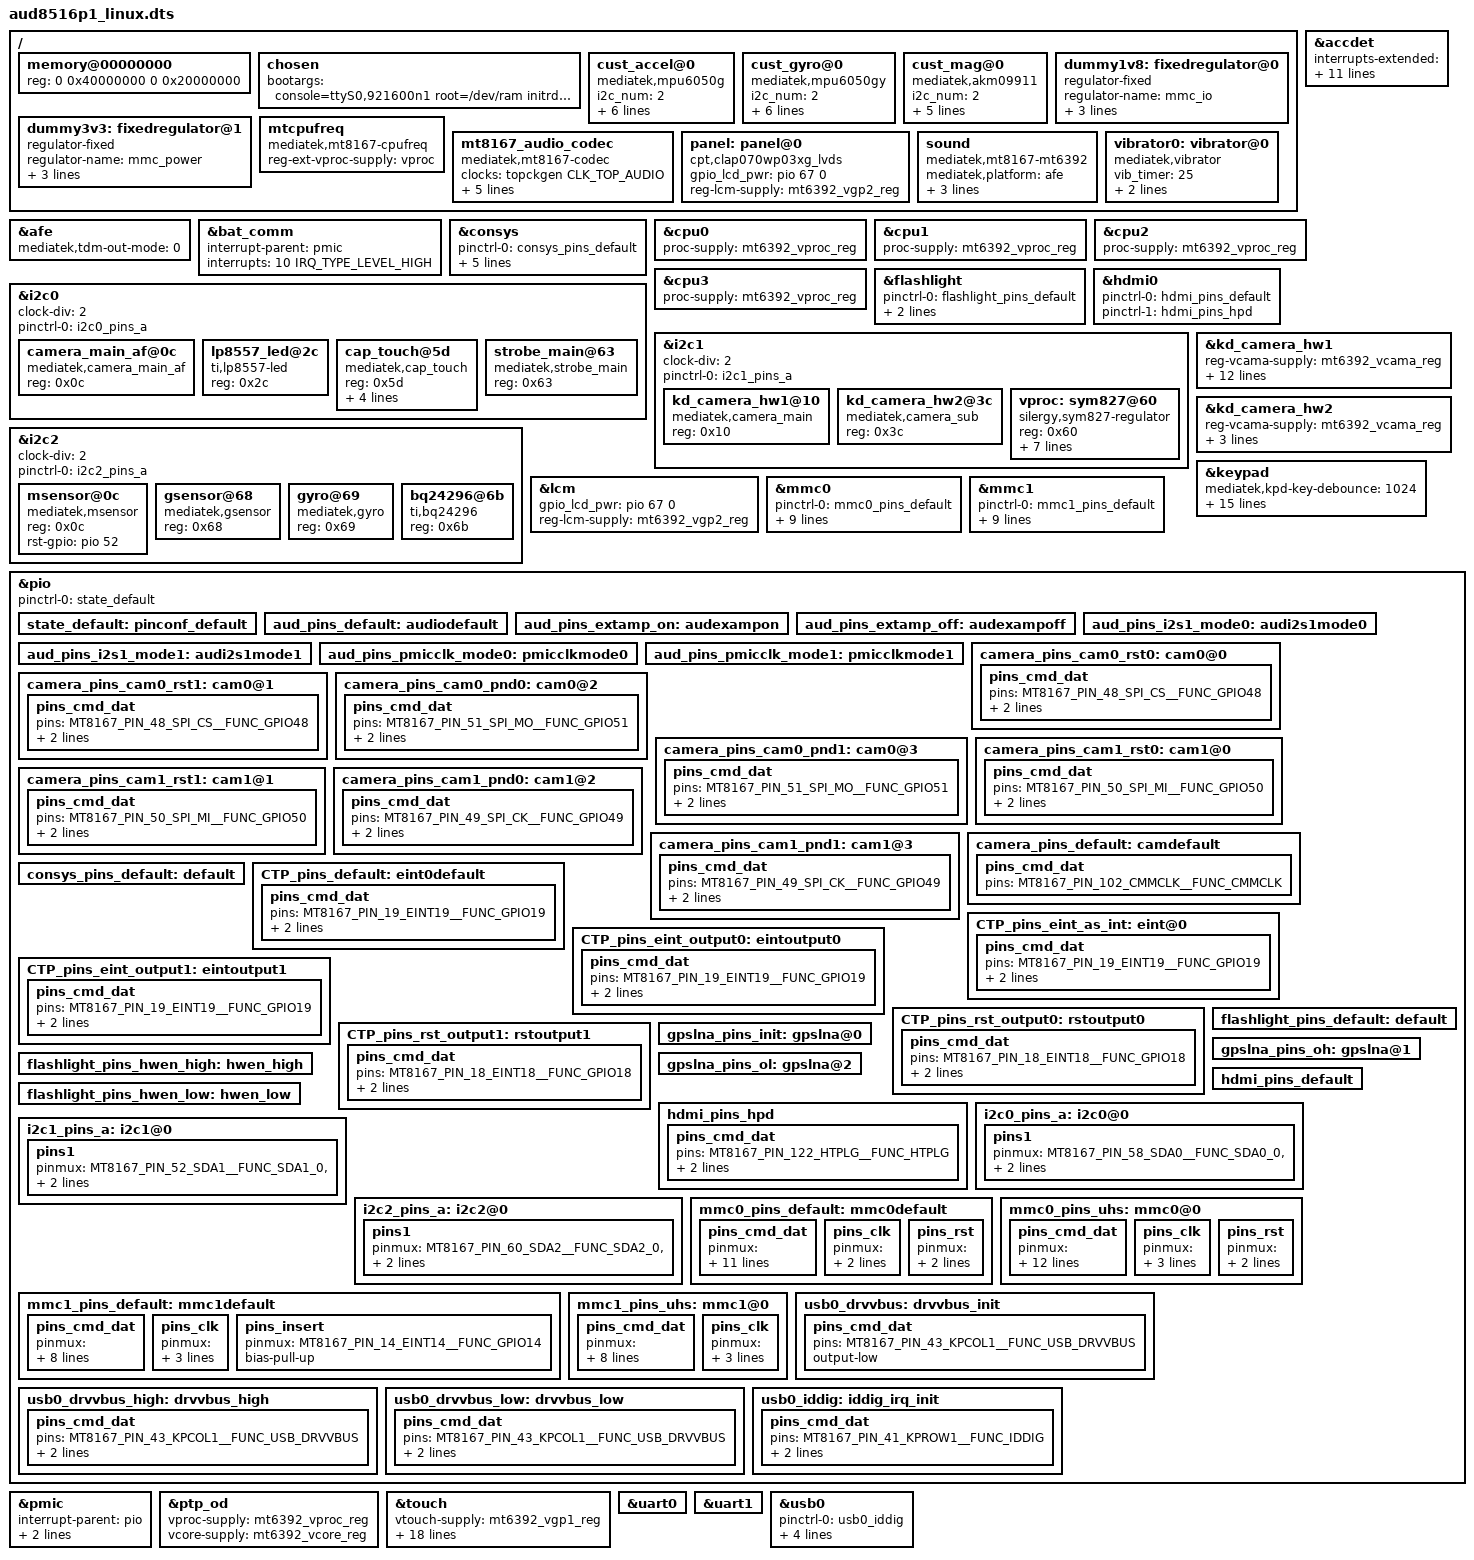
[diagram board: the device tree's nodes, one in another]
/*
 * Copyright (c) 2014-2015 MediaTek Inc.
 *
 * This program is free software; you can redistribute it and/or modify
 * it under the terms of the GNU General Public License version 2 as
 * published by the Free Software Foundation.
 *
 * This program is distributed in the hope that it will be useful,
 * MERCHANTABILITY or FITNESS FOR A PARTICULAR PURPOSE.  See the
 * GNU General Public License for more details.
 */

/dts-v1/;

#include "mt8167.dtsi"
#include "mt6392.dtsi"
#include "aud8516p1_linux_bat_setting.dtsi"

/ {
	memory@00000000 {
		device_type = "memory";
		reg = <0 0x40000000 0 0x20000000>;
	};

	/* chosen */
	chosen {
		bootargs = "console=ttyS0,921600n1 root=/dev/ram initrd=0x44000200,0x200000";
	};

/* sensor standardization */
	cust_accel@0 {
		compatible = "mediatek,mpu6050g";
		i2c_num	= <2>;
		i2c_addr = <0x68 0 0 0>;
		direction = <7>;
		power_id = <0xffff>;
		power_vol = <0>;
		firlen = <0>;
		is_batch_supported = <0>;
	};

	cust_gyro@0 {
		compatible = "mediatek,mpu6050gy";
		i2c_num = <2>;
		i2c_addr = <0x68 0 0 0>;
		direction = <7>;
		power_id = <0xffff>;
		power_vol = <0>;
		firlen = <0>;
		is_batch_supported = <0>;
	};

	cust_mag@0 {
		compatible = "mediatek,akm09911";
		i2c_num = <2>;
		i2c_addr = <0x0C 0 0 0>;
		direction = <6>;
		power_id = <0xffff>;
		power_vol = <0>;
		is_batch_supported			= <0>;
	};
/* sensor gpio standization */

	dummy1v8: fixedregulator@0 {
		compatible = "regulator-fixed";
		regulator-name = "mmc_io";
		regulator-min-microvolt = <1800000>;
		regulator-max-microvolt = <1800000>;
		regulator-always-on;
	};

	dummy3v3: fixedregulator@1 {
		compatible = "regulator-fixed";
		regulator-name = "mmc_power";
		regulator-min-microvolt = <3300000>;
		regulator-max-microvolt = <3300000>;
		regulator-always-on;
	};

	mtcpufreq {
		compatible = "mediatek,mt8167-cpufreq";
		reg-ext-vproc-supply = <&vproc>;
	};

	mt8167_audio_codec: mt8167_audio_codec {
		compatible = "mediatek,mt8167-codec";
		clocks = <&topckgen CLK_TOP_AUDIO>;
		clock-names = "bus";
		mediatek,afe-regmap = <&afe>;
		mediatek,apmixedsys-regmap = <&apmixedsys>;
		mediatek,pwrap-regmap = <&pwrap>;
		mediatek,speaker-mode = <0>; /* 0(CLASSD) 1(CLASSAB) */
		mediatek,dmic-wire-mode = <1>; /* 0(ONE_WIRE) 1(TWO_WIRE) */
	};

	panel: panel@0 {
		compatible = "cpt,clap070wp03xg_lvds";
		gpio_lcd_pwr = <&pio 67 0>;
		reg-lcm-supply = <&mt6392_vgp2_reg>;
	};

	sound: sound {
		compatible = "mediatek,mt8167-mt6392";
		mediatek,platform = <&afe>;
		pinctrl-names = "default", "extamp_on", "extamp_off";
		pinctrl-0 = <&aud_pins_default>;
		pinctrl-1 = <&aud_pins_extamp_on>;
		pinctrl-2 = <&aud_pins_extamp_off>;
		status = "okay";
	};

	vibrator0:vibrator@0 {
		compatible = "mediatek,vibrator";
		vib_timer = <25>;
		vib_limit = <9>;
		vib_vol= <5>;
	};
};

&accdet {
	interrupts-extended = <&sysirq GIC_SPI 152 IRQ_TYPE_LEVEL_LOW>,
			<&pio 16 IRQ_TYPE_LEVEL_HIGH>;
	eint-debounce = <256000>;
	accdet-gpio = <&pio 16 0>;
	accdet-mic-vol = <7>;
	headset-mode-setting = <0x500 0x500 1 0x1f0 0x800 0x800 0x20>;
	accdet-plugout-debounce = <20>;
	/*1:ACC mode, 2:low cost without in bias, 6:low cost with in bias*/
	accdet-mic-mode = <1>;
	/*0--MD_MAX--UP_MAX--DW_MAX*/
	headset-three-key-threshold = <0 80 220 500>;
	/*0--MD_MAX--VOICE_MAX--UP_MAX--DW_MAX*/
	headset-four-key-threshold = <0 58 121 192 450>;
	status = "okay";
};

&afe {
	/* 0(HDMI) 1(I2S) 2(TDM) */
	mediatek,tdm-out-mode = <0>;
};

&bat_comm {
	interrupt-parent = <&pmic>;
	interrupts = <10 IRQ_TYPE_LEVEL_HIGH>;
};

&consys {
	pinctrl-names = "default", "gps_lna_state_init", "gps_lna_state_oh", "gps_lna_state_ol";
	pinctrl-0 = <&consys_pins_default>;
	pinctrl-1 = <&gpslna_pins_init>;
	pinctrl-2 = <&gpslna_pins_oh>;
	pinctrl-3 = <&gpslna_pins_ol>;
	vcn18-supply = <&mt6392_vcn18_reg>;
	vcn35-supply = <&mt6392_vcn35_reg>;
	status = "okay";
};

&cpu0 {
	proc-supply = <&mt6392_vproc_reg>;
};

&cpu1 {
	proc-supply = <&mt6392_vproc_reg>;
};

&cpu2 {
	proc-supply = <&mt6392_vproc_reg>;
};

&cpu3 {
	proc-supply = <&mt6392_vproc_reg>;
};

&flashlight {
	pinctrl-names = "default", "hwen_high", "hwen_low";
	pinctrl-0 = <&flashlight_pins_default>;
	pinctrl-1 = <&flashlight_pins_hwen_high>;
	pinctrl-2 = <&flashlight_pins_hwen_low>;
	status = "okay";
};

&hdmi0 {
	pinctrl-names = "default", "hdmi_hpd";
	pinctrl-0 = <&hdmi_pins_default>;
	pinctrl-1 = <&hdmi_pins_hpd>;
	status = "okay";
};

&i2c0 {
	clock-div = <2>;
	pinctrl-names = "default";
	pinctrl-0 = <&i2c0_pins_a>;
	status = "okay";

	camera_main_af@0c {
		compatible = "mediatek,camera_main_af";
		reg = <0x0c>;
	};

	lp8557_led@2c {
		compatible = "ti,lp8557-led";
		reg = <0x2c>;
	};

	cap_touch@5d {
		compatible = "mediatek,cap_touch";
		reg = <0x5d>;
		interrupt-parent = <&pio>;
		interrupts = <19 IRQ_TYPE_EDGE_FALLING>;
		int-gpio = <&pio 19 0>;
		rst-gpio = <&pio 18 0>;
	};

	strobe_main@63 {
		compatible = "mediatek,strobe_main";
		reg = <0x63>;
	};
};

&i2c1 {
	clock-div = <2>;
	pinctrl-names = "default";
	pinctrl-0 = <&i2c1_pins_a>;
	status = "okay";

	kd_camera_hw1@10 {
		compatible = "mediatek,camera_main";
		reg = <0x10>;
	};

	kd_camera_hw2@3c {
		compatible = "mediatek,camera_sub";
		reg = <0x3c>;
	};

	vproc: sym827@60 {
		compatible = "silergy,sym827-regulator";
		reg = <0x60>;
		regulator-name = "vproc";
		regulator-min-microvolt = <600000>;
		regulator-max-microvolt = <1387500>;
		regulator-enable-ramp-delay = <400>;
		regulator-ramp-delay = <8333>;
		regulator-always-on;
		vsel-gpio = <&pio 34 0>;
	};
};

&i2c2 {
	clock-div = <2>;
	pinctrl-names = "default";
	pinctrl-0 = <&i2c2_pins_a>;
	status = "okay";

	msensor@0c {
		compatible = "mediatek,msensor";
		reg = <0x0c>;
		rst-gpio = <&pio 52 0>;
	};

	gsensor@68 {
		compatible = "mediatek,gsensor";
		reg = <0x68>;
	};

	gyro@69 {
		compatible = "mediatek,gyro";
		reg = <0x69>;
	};

	bq24296@6b {
		compatible = "ti,bq24296";
		reg = <0x6b>;
	};
};

/* Main Cam */
&kd_camera_hw1 {
	reg-vcama-supply = <&mt6392_vcama_reg>;		/* AVDD */
	reg-vcamd-supply = <&mt6392_vcamd_reg>;		/* DVDD */
	reg-vcamio-supply = <&mt6392_vcamio_reg>;	/* DOVDD */
	reg-vcamaf-supply = <&mt6392_vcamaf_reg>;	/* AFVDD */

	pinctrl-names = "default", "cam0_rst0", "cam0_rst1", "cam0_pnd0", "cam0_pnd1",
			"cam1_rst0", "cam1_rst1", "cam1_pnd0", "cam1_pnd1", "cam_ldo0_0", "cam_ldo0_1";
	pinctrl-0 = <&camera_pins_default>;
	pinctrl-1 = <&camera_pins_cam0_rst0>;
	pinctrl-2 = <&camera_pins_cam0_rst1>;
	pinctrl-3 = <&camera_pins_cam0_pnd0>;
	pinctrl-4 = <&camera_pins_cam0_pnd1>;
	pinctrl-5 = <&camera_pins_cam1_rst0>;
	pinctrl-6 = <&camera_pins_cam1_rst1>;
	pinctrl-7 = <&camera_pins_cam1_pnd0>;
	pinctrl-8 = <&camera_pins_cam1_pnd1>;
	status = "okay";
};

/* Sub Cam */
/* Same power pins as Main, actually, it can be commented */
&kd_camera_hw2{
	reg-vcama-supply = <&mt6392_vcama_reg>;		/* AVDD */
	reg-vcamd-supply = <&mt6392_vcamd_reg>;		/* DVDD */
	reg-vcamio-supply = <&mt6392_vcamio_reg>;	/* DOVDD */
	reg-vcamaf-supply = <&mt6392_vcamaf_reg>;	/* AFVDD */
};

&keypad {
	mediatek,kpd-key-debounce = <1024>;
	mediatek,kpd-sw-pwrkey = <116>;
	mediatek,kpd-hw-pwrkey = <8>;
	mediatek,kpd-sw-rstkey  = <114>;
	mediatek,kpd-hw-rstkey = <17>;
	mediatek,kpd-use-extend-type = <0>;
	/*HW Keycode [0~71] -> Linux Keycode*/
	mediatek,kpd-hw-map-num = <72>;
	mediatek,kpd-hw-init-map = <115 0 0 0 0 0 0 0 0 0 0 0 0 0 0 0 0 0 0 0 0 0 0 0
			0 0 0 0 0 0 0 0 0 0 0 0 0 0 0 0 0 0 0 0 0 0 0 0
			0 0 0 0 0 0 0 0 0 0 0 0 0 0 0 0 0 0 0 0 0 0 0 0 >;
	mediatek,kpd-pwrkey-eint-gpio = <0>;
	mediatek,kpd-pwkey-gpio-din  = <0>;
	mediatek,kpd-hw-dl-key0 = <0>;
	mediatek,kpd-hw-dl-key1 = <17>;
	mediatek,kpd-hw-dl-key2 = <8>;
	mediatek,kpd-hw-recovery-key = <17>;
	mediatek,kpd-hw-factory-key  = <0>;
};

&lcm {
	gpio_lcd_pwr = <&pio 67 0>;
	reg-lcm-supply = <&mt6392_vgp2_reg>;
};

&mmc0 {
	pinctrl-names = "default", "state_uhs";
	pinctrl-0 = <&mmc0_pins_default>;
	pinctrl-1 = <&mmc0_pins_uhs>;
	status = "okay";
	bus-width = <8>;
	max-frequency = <200000000>;
	cap-mmc-highspeed;
	mmc-hs200-1_8v;
	cap-mmc-hw-reset;
	vmmc-supply = <&mt6392_vemc3v3_reg>;
	vqmmc-supply = <&mt6392_vio18_reg>;
	non-removable;
};

&mmc1 {
	pinctrl-names = "default", "state_uhs";
	pinctrl-0 = <&mmc1_pins_default>;
	pinctrl-1 = <&mmc1_pins_uhs>;
	status = "okay";
	bus-width = <4>;
	max-frequency = <200000000>;
	cap-sd-highspeed;
	sd-uhs-sdr50;
	sd-uhs-sdr104;
	cd-gpios = <&pio 14 0>;
	vmmc-supply = <&mt6392_vmch_reg>;
	vqmmc-supply = <&mt6392_vmc_reg>;
};

&pio {
	pinctrl-names = "default";
	pinctrl-0 = <&state_default>;

	state_default:pinconf_default {
	};

	aud_pins_default: audiodefault {
	};

	aud_pins_extamp_on: audexampon {
	};

	aud_pins_extamp_off: audexampoff {
	};

	aud_pins_i2s1_mode0: audi2s1mode0 {
	};

	aud_pins_i2s1_mode1: audi2s1mode1 {
	};

	aud_pins_pmicclk_mode0: pmicclkmode0 {
	};

	aud_pins_pmicclk_mode1: pmicclkmode1 {
	};

	/* CAMERA GPIO standardization */
	/* Project Dependency : tb8167m1 */
	camera_pins_cam0_rst0: cam0@0 {
		pins_cmd_dat {
			pins = <MT8167_PIN_48_SPI_CS__FUNC_GPIO48>;/*GPIO_CAMERA_CMRST_PIN*/
			slew-rate = <1>; /*direction 0:in, 1:out*/
			output-low;/*direction out used only. output_low or high*/
		};
	};
	camera_pins_cam0_rst1: cam0@1 {
		pins_cmd_dat {
			pins = <MT8167_PIN_48_SPI_CS__FUNC_GPIO48>;/*GPIO_CAMERA_CMRST_PIN*/
			slew-rate = <1>;
			output-high;
		};
	};
	camera_pins_cam0_pnd0: cam0@2 {
		pins_cmd_dat {
			pins = <MT8167_PIN_51_SPI_MO__FUNC_GPIO51>;/*GPIO_CAMERA_CMPDN_PIN*/
			slew-rate = <1>;
			output-low;
		};
	};
	camera_pins_cam0_pnd1: cam0@3 {
		pins_cmd_dat {
			pins = <MT8167_PIN_51_SPI_MO__FUNC_GPIO51>;/*GPIO_CAMERA_CMPDN_PIN*/
			slew-rate = <1>;
			output-high;
		};
	};
	camera_pins_cam1_rst0: cam1@0 {
		pins_cmd_dat {
			pins = <MT8167_PIN_50_SPI_MI__FUNC_GPIO50>;/*GPIO_CAMERA_CMRST1_PIN*/
			slew-rate = <1>; /*direction 0:in, 1:out*/
			output-low;/*direction out used only. output_low or high*/
		};
	};
	camera_pins_cam1_rst1: cam1@1 {
		pins_cmd_dat {
			pins = <MT8167_PIN_50_SPI_MI__FUNC_GPIO50>;/*GPIO_CAMERA_CMRST1_PIN*/
			slew-rate = <1>;
			output-high;
		};
	};
	camera_pins_cam1_pnd0: cam1@2 {
		pins_cmd_dat {
			pins = <MT8167_PIN_49_SPI_CK__FUNC_GPIO49>;/*GPIO_CAMERA_CMPDN1_PIN*/
			slew-rate = <1>;
			output-low;
		};
	};
	camera_pins_cam1_pnd1: cam1@3 {
		pins_cmd_dat {
			pins = <MT8167_PIN_49_SPI_CK__FUNC_GPIO49>;/*GPIO_CAMERA_CMPDN1_PIN*/
			slew-rate = <1>;
			output-high;
		};
	};

	/* Set MCLK Pin default mode */
	camera_pins_default: camdefault {
		pins_cmd_dat {
			pins = <MT8167_PIN_102_CMMCLK__FUNC_CMMCLK>;	/*MCLK*/
		};
	};

	/* CONSYS GPIO Settings - Start */
	consys_pins_default: default {

	};
	/* CONSYS GPIO Settings - End */

	CTP_pins_default: eint0default {
		pins_cmd_dat {
			pins = <MT8167_PIN_19_EINT19__FUNC_GPIO19>;
			slew-rate = <0>;
			bias-disable;
		};
	};

	CTP_pins_eint_as_int: eint@0 {
		pins_cmd_dat {
			pins = <MT8167_PIN_19_EINT19__FUNC_GPIO19>;
			slew-rate = <0>;
			bias-disable;
		};
	};

	CTP_pins_eint_output0: eintoutput0 {
		pins_cmd_dat {
			pins = <MT8167_PIN_19_EINT19__FUNC_GPIO19>;
			slew-rate = <1>;
			output-low;
		};
	};

	CTP_pins_eint_output1: eintoutput1 {
		pins_cmd_dat {
			pins = <MT8167_PIN_19_EINT19__FUNC_GPIO19>;
			slew-rate = <1>;
			output-high;
		};
	};

	CTP_pins_rst_output0: rstoutput0 {
		pins_cmd_dat {
			pins = <MT8167_PIN_18_EINT18__FUNC_GPIO18>;
			slew-rate = <1>;
			output-low;
		};
	};

	CTP_pins_rst_output1: rstoutput1 {
		pins_cmd_dat {
			pins = <MT8167_PIN_18_EINT18__FUNC_GPIO18>;
			slew-rate = <1>;
			output-high;
		};
	};

	flashlight_pins_default: default {
	};

	flashlight_pins_hwen_high: hwen_high {
	};

	flashlight_pins_hwen_low: hwen_low {
	};

	/* CONSYS GPIO Settings - Start */
	gpslna_pins_init: gpslna@0 {
	};

	gpslna_pins_oh: gpslna@1 {
	};

	gpslna_pins_ol: gpslna@2 {
	};
	/* CONSYS GPIO Settings - End */

	hdmi_pins_default: hdmi_pins_default {
	};

	hdmi_pins_hpd: hdmi_pins_hpd {
		pins_cmd_dat {
			pins = <MT8167_PIN_122_HTPLG__FUNC_HTPLG>;
			slew-rate = <0>;
			bias-pull-down;
		};
	};

	i2c0_pins_a: i2c0@0 {
		pins1 {
			pinmux = <MT8167_PIN_58_SDA0__FUNC_SDA0_0>,
				 <MT8167_PIN_59_SCL0__FUNC_SCL0_0>;
			bias-disable;
		};
	};

	i2c1_pins_a: i2c1@0 {
		pins1 {
			pinmux = <MT8167_PIN_52_SDA1__FUNC_SDA1_0>,
				 <MT8167_PIN_53_SCL1__FUNC_SCL1_0>;
			bias-disable;
		};
	};

	i2c2_pins_a: i2c2@0 {
		pins1 {
			pinmux = <MT8167_PIN_60_SDA2__FUNC_SDA2_0>,
				 <MT8167_PIN_61_SCL2__FUNC_SCL2_0>;
			bias-disable;
		};
	};

	mmc0_pins_default: mmc0default {
		pins_cmd_dat {
			pinmux = <MT8167_PIN_120_MSDC0_DAT0__FUNC_MSDC0_DAT0>,
				<MT8167_PIN_119_MSDC0_DAT1__FUNC_MSDC0_DAT1>,
				<MT8167_PIN_118_MSDC0_DAT2__FUNC_MSDC0_DAT2>,
				<MT8167_PIN_117_MSDC0_DAT3__FUNC_MSDC0_DAT3>,
				<MT8167_PIN_113_MSDC0_DAT4__FUNC_MSDC0_DAT4>,
				<MT8167_PIN_112_MSDC0_DAT5__FUNC_MSDC0_DAT5>,
				<MT8167_PIN_111_MSDC0_DAT6__FUNC_MSDC0_DAT6>,
				<MT8167_PIN_110_MSDC0_DAT7__FUNC_MSDC0_DAT7>,
				<MT8167_PIN_115_MSDC0_CMD__FUNC_MSDC0_CMD>;
			input-enable;
			bias-pull-up;
		};

		pins_clk {
			pinmux = <MT8167_PIN_116_MSDC0_CLK__FUNC_MSDC0_CLK>;
			bias-pull-down;
		};

		pins_rst {
			pinmux = <MT8167_PIN_114_MSDC0_RSTB__FUNC_MSDC0_RSTB>;
			bias-pull-up;
		};
	};

	mmc0_pins_uhs: mmc0@0{
		pins_cmd_dat {
			pinmux = <MT8167_PIN_120_MSDC0_DAT0__FUNC_MSDC0_DAT0>,
				<MT8167_PIN_119_MSDC0_DAT1__FUNC_MSDC0_DAT1>,
				<MT8167_PIN_118_MSDC0_DAT2__FUNC_MSDC0_DAT2>,
				<MT8167_PIN_117_MSDC0_DAT3__FUNC_MSDC0_DAT3>,
				<MT8167_PIN_113_MSDC0_DAT4__FUNC_MSDC0_DAT4>,
				<MT8167_PIN_112_MSDC0_DAT5__FUNC_MSDC0_DAT5>,
				<MT8167_PIN_111_MSDC0_DAT6__FUNC_MSDC0_DAT6>,
				<MT8167_PIN_110_MSDC0_DAT7__FUNC_MSDC0_DAT7>,
				<MT8167_PIN_115_MSDC0_CMD__FUNC_MSDC0_CMD>;
			input-enable;
			drive-strength = <MTK_DRIVE_6mA>;
			bias-pull-up = <MTK_PUPD_SET_R1R0_01>;
		};

		pins_clk {
			pinmux = <MT8167_PIN_116_MSDC0_CLK__FUNC_MSDC0_CLK>;
			drive-strength = <MTK_DRIVE_8mA>;
			bias-pull-down = <MTK_PUPD_SET_R1R0_10>;
		};

		pins_rst {
			pinmux = <MT8167_PIN_114_MSDC0_RSTB__FUNC_MSDC0_RSTB>;
			bias-pull-up;
		};
	};

	mmc1_pins_default: mmc1default {
		pins_cmd_dat {
			pinmux = <MT8167_PIN_106_MSDC1_DAT0__FUNC_MSDC1_DAT0>,
				<MT8167_PIN_107_MSDC1_DAT1__FUNC_MSDC1_DAT1>,
				<MT8167_PIN_108_MSDC1_DAT2__FUNC_MSDC1_DAT2>,
				<MT8167_PIN_109_MSDC1_DAT3__FUNC_MSDC1_DAT3>,
				<MT8167_PIN_104_MSDC1_CMD__FUNC_MSDC1_CMD>;
			input-enable;
			drive-strength = <MTK_DRIVE_6mA>;
			bias-pull-up = <MTK_PUPD_SET_R1R0_01>;
		};

		pins_clk {
			pinmux = <MT8167_PIN_105_MSDC1_CLK__FUNC_MSDC1_CLK>;
			drive-strength = <MTK_DRIVE_6mA>;
			bias-pull-down = <MTK_PUPD_SET_R1R0_10>;
		};

		pins_insert {
			pinmux = <MT8167_PIN_14_EINT14__FUNC_GPIO14>;
			bias-pull-up;
		};
	};

	mmc1_pins_uhs: mmc1@0 {
		pins_cmd_dat {
			pinmux = <MT8167_PIN_106_MSDC1_DAT0__FUNC_MSDC1_DAT0>,
				<MT8167_PIN_107_MSDC1_DAT1__FUNC_MSDC1_DAT1>,
				<MT8167_PIN_108_MSDC1_DAT2__FUNC_MSDC1_DAT2>,
				<MT8167_PIN_109_MSDC1_DAT3__FUNC_MSDC1_DAT3>,
				<MT8167_PIN_104_MSDC1_CMD__FUNC_MSDC1_CMD>;
			input-enable;
			drive-strength = <MTK_DRIVE_6mA>;
			bias-pull-up = <MTK_PUPD_SET_R1R0_01>;
		};

		pins_clk {
			pinmux = <MT8167_PIN_105_MSDC1_CLK__FUNC_MSDC1_CLK>;
			drive-strength = <MTK_DRIVE_8mA>;
			bias-pull-down = <MTK_PUPD_SET_R1R0_10>;
		};
	};

/* USB GPIO start */
	usb0_drvvbus: drvvbus_init {
		pins_cmd_dat {
			pins = <MT8167_PIN_43_KPCOL1__FUNC_USB_DRVVBUS>;
			output-low;
		};
	};

	usb0_drvvbus_high: drvvbus_high {
		pins_cmd_dat {
			pins = <MT8167_PIN_43_KPCOL1__FUNC_USB_DRVVBUS>;
			slew-rate = <1>;
			output-high;
		};
	};

	usb0_drvvbus_low: drvvbus_low {
		pins_cmd_dat {
			pins = <MT8167_PIN_43_KPCOL1__FUNC_USB_DRVVBUS>;
			slew-rate = <1>;
			output-low;
		};
	};

	usb0_iddig: iddig_irq_init {
		pins_cmd_dat {
			pins = <MT8167_PIN_41_KPROW1__FUNC_IDDIG>;
			slew-rate = <0>;
			bias-pull-up = <00>;
		};
	};
/* USB GPIO end */
};

&pmic {
	interrupt-parent = <&pio>;
	interrupts = <28 IRQ_TYPE_LEVEL_HIGH>;
	interrupt-controller;
	#interrupt-cells = <2>;
};

&ptp_od {
	vproc-supply = <&mt6392_vproc_reg>;
	vcore-supply = <&mt6392_vcore_reg>;
};

&touch {
	vtouch-supply = <&mt6392_vgp1_reg>;
	tpd-resolution = <800 1280>;
	use-tpd-button = <0>;
	tpd-key-num = <4>;
	tpd-key-local= <139 172 158 0>;
	tpd-key-dim-local = <60 850 50 30 180 850 50 30 300 850 50 30 420 850 50 30>;
	tpd-max-touch-num = <5>;
	tpd-filter-enable = <1>;
	tpd-filter-pixel-density = <124>;
	tpd-filter-custom-prameters = <0 0 0 0 0 0 0 0 0 0 0 0>;
	tpd-filter-custom-speed = <0 0 0>;
	pinctrl-names = "default", "state_eint_as_int", "state_eint_output0", "state_eint_output1",
		"state_rst_output0", "state_rst_output1";
	pinctrl-0 = <&CTP_pins_default>;
	pinctrl-1 = <&CTP_pins_eint_as_int>;
	pinctrl-2 = <&CTP_pins_eint_output0>;
	pinctrl-3 = <&CTP_pins_eint_output1>;
	pinctrl-4 = <&CTP_pins_rst_output0>;
	pinctrl-5 = <&CTP_pins_rst_output1>;
	status = "okay";
};

&uart0 {
	status="okay";
};

&uart1 {
	status="okay";
};

&usb0 {
	pinctrl-names = "iddig_irq_init", "drvvbus_init", "drvvbus_low", "drvvbus_high";
	pinctrl-0 = <&usb0_iddig>;
	pinctrl-1 = <&usb0_drvvbus>;
	pinctrl-2 = <&usb0_drvvbus_low>;
	pinctrl-3 = <&usb0_drvvbus_high>;
	status = "okay";
	drvvbus_gpio = <&pio 43 2>;
};
